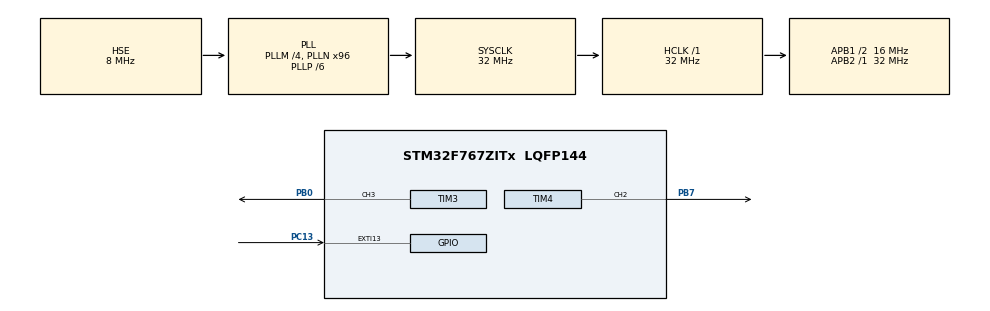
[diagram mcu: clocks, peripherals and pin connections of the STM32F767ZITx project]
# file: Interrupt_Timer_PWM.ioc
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Mcu.Family=STM32F7
Mcu.Name=STM32F767ZITx
Mcu.Package=LQFP144
NVIC.EXTI15_10_IRQn=true\:0\:0\:false\:false\:true\:true\:true
NVIC.PriorityGroup=NVIC_PRIORITYGROUP_4
PB0.Signal=S_TIM3_CH3
PB7.Signal=S_TIM4_CH2
PC13.Signal=GPXTI13
PH0/OSC_IN.Mode=HSE-External-Oscillator
PH0/OSC_IN.Signal=RCC_OSC_IN
PH1/OSC_OUT.Mode=HSE-External-Oscillator
PH1/OSC_OUT.Signal=RCC_OSC_OUT
ProjectManager.HeapSize=0x200
ProjectManager.StackSize=0x400
ProjectManager.TargetToolchain=STM32CubeIDE
RCC.AHBFreq_Value=32000000
RCC.APB1CLKDivider=RCC_HCLK_DIV2
RCC.APB1Freq_Value=16000000
RCC.APB1TimFreq_Value=32000000
RCC.APB2Freq_Value=32000000
RCC.APB2TimFreq_Value=32000000
RCC.CortexFreq_Value=32000000
RCC.HCLKFreq_Value=32000000
RCC.HSE_VALUE=8000000
RCC.HSI_VALUE=16000000
RCC.LSE_VALUE=32768
RCC.PLLM=4
RCC.PLLN=96
RCC.PLLP=RCC_PLLP_DIV6
RCC.PLLSourceVirtual=RCC_PLLSOURCE_HSE
RCC.SYSCLKFreq_VALUE=32000000
RCC.SYSCLKSource=RCC_SYSCLKSOURCE_PLLCLK
RCC.USBFreq_Value=96000000
RCC.VCOOutputFreq_Value=192000000
SH.S_TIM3_CH3.0=TIM3_CH3,PWM Generation3 CH3
SH.S_TIM4_CH2.0=TIM4_CH2,PWM Generation2 CH2
TIM3.Channel-PWM\ Generation3\ CH3=TIM_CHANNEL_3
TIM3.Period=100
TIM3.Prescaler=32
TIM3.Pulse-PWM\ Generation3\ CH3=100
TIM4.Channel-PWM\ Generation2\ CH2=TIM_CHANNEL_2
TIM4.Period=100
TIM4.Prescaler=32
TIM4.Pulse-PWM\ Generation2\ CH2=50
VP_TIM3_VS_ClockSourceINT.Mode=Internal
VP_TIM4_VS_ClockSourceINT.Mode=Internal
board=custom

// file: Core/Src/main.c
/* USER CODE BEGIN Header */
/**
  ******************************************************************************
  * @file           : main.c
  * @brief          : Main program body
  ******************************************************************************
  * @attention
  *
  * <h2><center>&copy; Copyright (c) 2020 STMicroelectronics.
  * All rights reserved.</center></h2>
  *
  * This software component is licensed by ST under BSD 3-Clause license,
  * the "License"; You may not use this file except in compliance with the
  * License. You may obtain a copy of the License at:
  *                        opensource.org/licenses/BSD-3-Clause
  *
  ******************************************************************************
  */
/* USER CODE END Header */

#include "main.h"

TIM_HandleTypeDef htim3;
TIM_HandleTypeDef htim4;

/* USER CODE BEGIN PV */
int duty_cycle = 0;
/* USER CODE END PV */

void SystemClock_Config(void);
static void MX_GPIO_Init(void);
static void MX_TIM3_Init(void);
static void MX_TIM4_Init(void);

int main(void)
{

  /* MCU Configuration--------------------------------------------------------*/

  /* Reset of all peripherals, Initializes the Flash interface and the Systick. */
  HAL_Init();

  /* Configure the system clock */
  SystemClock_Config();

  /* Initialize all configured peripherals */
  MX_GPIO_Init();
  MX_TIM3_Init();
  MX_TIM4_Init();
  /* USER CODE BEGIN 2 */

 HAL_TIM_PWM_Start(&htim3,TIM_CHANNEL_3);
 HAL_TIM_PWM_Start(&htim4,TIM_CHANNEL_2);

  /* USER CODE END 2 */

  /* Infinite loop */
  /* USER CODE BEGIN WHILE */
  while (1)
  {
	  //First - change of brightnes os LEDs
	  /*htim4.Instance->CCR2 = 10;
	  htim3.Instance->CCR3 = 90;
	  HAL_Delay(5000);
	  htim4.Instance->CCR2 = 90;
	  htim3.Instance->CCR3 = 20;
	  HAL_Delay(5000);*/
	  //-----------------------

	 // htim3.Instance->CCR3 = duty_cycle;

	  for(int i =0;i<100;i++){
		  htim4.Instance ->CCR2 = i;
		  htim3.Instance->CCR3 = duty_cycle;
		  HAL_Delay(50);
		  if(i>=100) i=0;
	  }
    /* USER CODE END WHILE */

  }
}

void SystemClock_Config(void)
{
  RCC_OscInitTypeDef RCC_OscInitStruct = {0};
  RCC_ClkInitTypeDef RCC_ClkInitStruct = {0};

  /** Configure the main internal regulator output voltage
  */
  __HAL_RCC_PWR_CLK_ENABLE();
  __HAL_PWR_VOLTAGESCALING_CONFIG(PWR_REGULATOR_VOLTAGE_SCALE3);
  /** Initializes the CPU, AHB and APB busses clocks
  */
  RCC_OscInitStruct.OscillatorType = RCC_OSCILLATORTYPE_HSE;
  RCC_OscInitStruct.HSEState = RCC_HSE_ON;
  RCC_OscInitStruct.PLL.PLLState = RCC_PLL_ON;
  RCC_OscInitStruct.PLL.PLLSource = RCC_PLLSOURCE_HSE;
  RCC_OscInitStruct.PLL.PLLM = 4;
  RCC_OscInitStruct.PLL.PLLN = 96;
  RCC_OscInitStruct.PLL.PLLP = RCC_PLLP_DIV6;
  RCC_OscInitStruct.PLL.PLLQ = 2;
  if (HAL_RCC_OscConfig(&RCC_OscInitStruct) != HAL_OK)
  {
    Error_Handler();
  }
  /** Initializes the CPU, AHB and APB busses clocks
  */
  RCC_ClkInitStruct.ClockType = RCC_CLOCKTYPE_HCLK|RCC_CLOCKTYPE_SYSCLK
                              |RCC_CLOCKTYPE_PCLK1|RCC_CLOCKTYPE_PCLK2;
  RCC_ClkInitStruct.SYSCLKSource = RCC_SYSCLKSOURCE_PLLCLK;
  RCC_ClkInitStruct.AHBCLKDivider = RCC_SYSCLK_DIV1;
  RCC_ClkInitStruct.APB1CLKDivider = RCC_HCLK_DIV2;
  RCC_ClkInitStruct.APB2CLKDivider = RCC_HCLK_DIV1;

  if (HAL_RCC_ClockConfig(&RCC_ClkInitStruct, FLASH_LATENCY_1) != HAL_OK)
  {
    Error_Handler();
  }
}

static void MX_TIM3_Init(void)
{

  TIM_ClockConfigTypeDef sClockSourceConfig = {0};
  TIM_MasterConfigTypeDef sMasterConfig = {0};
  TIM_OC_InitTypeDef sConfigOC = {0};

  htim3.Instance = TIM3;
  htim3.Init.Prescaler = 32;
  htim3.Init.CounterMode = TIM_COUNTERMODE_UP;
  htim3.Init.Period = 100;
  htim3.Init.ClockDivision = TIM_CLOCKDIVISION_DIV1;
  htim3.Init.AutoReloadPreload = TIM_AUTORELOAD_PRELOAD_DISABLE;
  if (HAL_TIM_Base_Init(&htim3) != HAL_OK)
  {
    Error_Handler();
  }
  sClockSourceConfig.ClockSource = TIM_CLOCKSOURCE_INTERNAL;
  if (HAL_TIM_ConfigClockSource(&htim3, &sClockSourceConfig) != HAL_OK)
  {
    Error_Handler();
  }
  if (HAL_TIM_PWM_Init(&htim3) != HAL_OK)
  {
    Error_Handler();
  }
  sMasterConfig.MasterOutputTrigger = TIM_TRGO_RESET;
  sMasterConfig.MasterSlaveMode = TIM_MASTERSLAVEMODE_DISABLE;
  if (HAL_TIMEx_MasterConfigSynchronization(&htim3, &sMasterConfig) != HAL_OK)
  {
    Error_Handler();
  }
  sConfigOC.OCMode = TIM_OCMODE_PWM1;
  sConfigOC.Pulse = 100;
  sConfigOC.OCPolarity = TIM_OCPOLARITY_HIGH;
  sConfigOC.OCFastMode = TIM_OCFAST_DISABLE;
  if (HAL_TIM_PWM_ConfigChannel(&htim3, &sConfigOC, TIM_CHANNEL_3) != HAL_OK)
  {
    Error_Handler();
  }
  HAL_TIM_MspPostInit(&htim3);

}

static void MX_TIM4_Init(void)
{

  TIM_ClockConfigTypeDef sClockSourceConfig = {0};
  TIM_MasterConfigTypeDef sMasterConfig = {0};
  TIM_OC_InitTypeDef sConfigOC = {0};

  htim4.Instance = TIM4;
  htim4.Init.Prescaler = 32;
  htim4.Init.CounterMode = TIM_COUNTERMODE_UP;
  htim4.Init.Period = 100;
  htim4.Init.ClockDivision = TIM_CLOCKDIVISION_DIV1;
  htim4.Init.AutoReloadPreload = TIM_AUTORELOAD_PRELOAD_DISABLE;
  if (HAL_TIM_Base_Init(&htim4) != HAL_OK)
  {
    Error_Handler();
  }
  sClockSourceConfig.ClockSource = TIM_CLOCKSOURCE_INTERNAL;
  if (HAL_TIM_ConfigClockSource(&htim4, &sClockSourceConfig) != HAL_OK)
  {
    Error_Handler();
  }
  if (HAL_TIM_PWM_Init(&htim4) != HAL_OK)
  {
    Error_Handler();
  }
  sMasterConfig.MasterOutputTrigger = TIM_TRGO_RESET;
  sMasterConfig.MasterSlaveMode = TIM_MASTERSLAVEMODE_DISABLE;
  if (HAL_TIMEx_MasterConfigSynchronization(&htim4, &sMasterConfig) != HAL_OK)
  {
    Error_Handler();
  }
  sConfigOC.OCMode = TIM_OCMODE_PWM1;
  sConfigOC.Pulse = 50;
  sConfigOC.OCPolarity = TIM_OCPOLARITY_HIGH;
  sConfigOC.OCFastMode = TIM_OCFAST_DISABLE;
  if (HAL_TIM_PWM_ConfigChannel(&htim4, &sConfigOC, TIM_CHANNEL_2) != HAL_OK)
  {
    Error_Handler();
  }
  HAL_TIM_MspPostInit(&htim4);

}

static void MX_GPIO_Init(void)
{
  GPIO_InitTypeDef GPIO_InitStruct = {0};

  /* GPIO Ports Clock Enable */
  __HAL_RCC_GPIOC_CLK_ENABLE();
  __HAL_RCC_GPIOH_CLK_ENABLE();
  __HAL_RCC_GPIOB_CLK_ENABLE();

  /*Configure GPIO pin : PC13 */
  GPIO_InitStruct.Pin = GPIO_PIN_13;
  GPIO_InitStruct.Mode = GPIO_MODE_IT_RISING;
  GPIO_InitStruct.Pull = GPIO_NOPULL;
  HAL_GPIO_Init(GPIOC, &GPIO_InitStruct);

  /* EXTI interrupt init*/
  HAL_NVIC_SetPriority(EXTI15_10_IRQn, 0, 0);
  HAL_NVIC_EnableIRQ(EXTI15_10_IRQn);

}

/* USER CODE BEGIN 4 */
void HAL_GPIO_EXTI_Callback(uint16_t GPIO_Pin)
{
  /* Prevent unused argument(s) compilation warning */
  UNUSED(GPIO_Pin);

  /* NOTE: This function Should not be modified, when the callback is needed,
           the HAL_GPIO_EXTI_Callback could be implemented in the user file

   */

	  duty_cycle = duty_cycle+5;
	  if(duty_cycle >= 100){
		  duty_cycle = 0;

	  for(int i = 0;i<10000;i++);
  }

}
/* USER CODE END 4 */

void Error_Handler(void)
{
}

/************************ (C) COPYRIGHT STMicroelectronics *****END OF FILE****/
